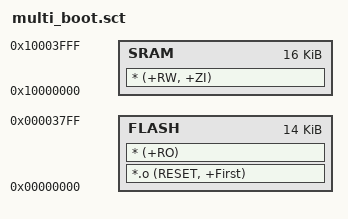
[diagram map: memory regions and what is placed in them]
;******************************************************************************
;
; multi_boot.sct
;
; Scatter file for Keil linker configuration.
;
;******************************************************************************

;******************************************************************************
;
; ${copyright}
;
; This is part of revision ${version} of the AmbiqSuite Development Package.
;
;******************************************************************************
LR_1 0x00000000
{
    FLASH 0x00000000 0x00003800
    {
        *.o (RESET, +First)
        * (+RO)
    }

    SRAM 0x10000000 0x00004000
    {
        * (+RW, +ZI)
    }
}

